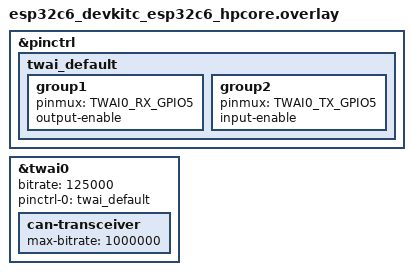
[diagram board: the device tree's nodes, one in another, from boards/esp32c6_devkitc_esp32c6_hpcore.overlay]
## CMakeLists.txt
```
# SPDX-License-Identifier: Apache-2.0

cmake_minimum_required(VERSION 3.20.0)
find_package(Zephyr REQUIRED HINTS $ENV{ZEPHYR_BASE})
project(app_more_services6)

zephyr_syscall_header(${CMAKE_CURRENT_SOURCE_DIR}/src/svc.h)

target_sources(app PRIVATE src/main.c src/svc.c)
```

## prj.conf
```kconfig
CONFIG_USERSPACE=y
CONFIG_APPLICATION_DEFINED_SYSCALL=y

CONFIG_CAN=y

CONFIG_LOG=y
CONFIG_LOG_MODE_MINIMAL=y
CONFIG_THREAD_NAME=y

CONFIG_MAIN_STACK_SIZE=4096
```

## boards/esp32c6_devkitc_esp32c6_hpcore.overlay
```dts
/*
 * Copyright (c) 2026 Espressif Systems (Shanghai) Co., Ltd.
 *
 * SPDX-License-Identifier: Apache-2.0
 */

#include <zephyr/dt-bindings/pinctrl/esp32c6-pinctrl.h>

/*
 * CAN/TWAI internal loopback: TX and RX are both muxed to GPIO5 (output and
 * input enabled on the same pin) so a sent frame is wired straight back to the
 * receiver. No external transceiver or bus is needed.
 */
&pinctrl {
	twai_default: twai_default {
		group1 {
			pinmux = <TWAI0_RX_GPIO5>;
			output-enable;
		};

		group2 {
			pinmux = <TWAI0_TX_GPIO5>;
			input-enable;
		};
	};
};

&twai0 {
	status = "okay";
	bitrate = <125000>;
	pinctrl-0 = <&twai_default>;
	pinctrl-names = "default";

	can-transceiver {
		max-bitrate = <1000000>;
	};
};
```

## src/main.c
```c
/*
 * Copyright (c) 2026 Espressif Systems (Shanghai) Co., Ltd.
 *
 * SPDX-License-Identifier: Apache-2.0
 */

/*
 * An app using the CAN bus through services from user mode. The platform owns
 * the controller, puts it in loopback, installs a receive filter feeding a
 * per-app queue, and starts it. The app sends frames and polls received ones,
 * passing only a scalar id and a byte payload across the user/kernel boundary.
 * Loopback echoes each sent frame back, so the demo runs with no wiring.
 */

#include "svc.h"

#include <zephyr/kernel.h>
#include <zephyr/sys/printk.h>

#define STACK_SIZE 2048
#define APP_PRIO   5

K_THREAD_STACK_DEFINE(app_stack, STACK_SIZE);
static struct k_thread app_thread;

static void app_entry(void *p1, void *p2, void *p3)
{
	ARG_UNUSED(p1); ARG_UNUSED(p2); ARG_UNUSED(p3);

	for (int round = 0; round < 4; round++) {
		uint8_t tx[4] = { 0x10 + round, 0x20, 0x30, 0x40 };
		uint32_t id = 0x123 + round;

		int sent = svc_can_send(id, tx, sizeof(tx));

		printk("  [app] round %d: sent id=0x%03x len=%d\n", round, id, sent);

		/* Give the loopback frame a moment to land in the queue. */
		k_msleep(50);

		uint32_t rid = 0;
		uint8_t rx[8] = { 0 };
		int n = svc_can_recv(&rid, rx, sizeof(rx));

		if (n >= 0) {
			printk("  [app] recv id=0x%03x len=%d data=", rid, n);
			for (int i = 0; i < n; i++) {
				printk("%02x ", rx[i]);
			}
			printk("\n");
		} else {
			printk("  [app] recv rc=%d\n", n);
		}

		k_msleep(300);
	}

	printk("  [app] done - used CAN send + receive\n");
}

int main(void)
{
	printk("\n*** more services 6: CAN bus (C6) ***\n");

	svc_can_install();

	k_tid_t t = k_thread_create(&app_thread, app_stack, STACK_SIZE, app_entry,
				    NULL, NULL, NULL, APP_PRIO, K_USER, K_FOREVER);

	k_thread_start(t);
	k_thread_join(t, K_FOREVER);

	printk("\n*** done ***\n");
	return 0;
}
```

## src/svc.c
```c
/*
 * Copyright (c) 2026 Espressif Systems (Shanghai) Co., Ltd.
 *
 * SPDX-License-Identifier: Apache-2.0
 */

#include "svc.h"

#include <zephyr/kernel.h>
#include <zephyr/device.h>
#include <zephyr/drivers/can.h>
#include <zephyr/internal/syscall_handler.h>
#include <string.h>
#include <errno.h>

#define CAN_PAYLOAD_MAX 8

/* The platform owns the CAN controller; the app reaches it through this seam. */
static const struct device *const can_dev = DEVICE_DT_GET(DT_NODELABEL(twai0));

/* Per-app receive queue: the platform's filter feeds frames here in S-mode. */
K_MSGQ_DEFINE(app_can_q, sizeof(struct can_frame), 8, 4);

void svc_can_install(void)
{
	if (!device_is_ready(can_dev)) {
		return;
	}

	/* Loopback self-test: a sent frame is received back, no bus needed. */
	(void)can_set_mode(can_dev, CAN_MODE_LOOPBACK);

	/* Accept every standard id; in a real grant this mask is scoped. */
	const struct can_filter filter = {
		.id = 0,
		.mask = 0,
		.flags = 0,
	};

	(void)can_add_rx_filter_msgq(can_dev, &app_can_q, &filter);
	(void)can_start(can_dev);
}

int z_impl_svc_can_send(uint32_t id, const uint8_t *buf, size_t len)
{
	if (!device_is_ready(can_dev) || len > CAN_PAYLOAD_MAX) {
		return -EINVAL;
	}

	struct can_frame frame = {
		.id = id,
		.dlc = (uint8_t)len,
		.flags = 0,
	};

	memcpy(frame.data, buf, len);

	int rc = can_send(can_dev, &frame, K_MSEC(100), NULL, NULL);

	return (rc == 0) ? (int)len : rc;
}

int z_impl_svc_can_recv(uint32_t *id_out, uint8_t *buf, size_t cap)
{
	struct can_frame frame;

	if (k_msgq_get(&app_can_q, &frame, K_NO_WAIT) != 0) {
		return -EAGAIN;
	}

	size_t n = MIN((size_t)frame.dlc, cap);

	*id_out = frame.id;
	memcpy(buf, frame.data, n);
	return (int)n;
}

#ifdef CONFIG_USERSPACE
static inline int z_vrfy_svc_can_send(uint32_t id, const uint8_t *buf, size_t len)
{
	if (len > CAN_PAYLOAD_MAX) {
		return -EINVAL;
	}
	K_OOPS(K_SYSCALL_MEMORY_READ(buf, len));
	return z_impl_svc_can_send(id, buf, len);
}
#include <zephyr/syscalls/svc_can_send_mrsh.c>

static inline int z_vrfy_svc_can_recv(uint32_t *id_out, uint8_t *buf, size_t cap)
{
	if (cap > CAN_PAYLOAD_MAX) {
		cap = CAN_PAYLOAD_MAX;
	}
	K_OOPS(K_SYSCALL_MEMORY_WRITE(id_out, sizeof(*id_out)));
	K_OOPS(K_SYSCALL_MEMORY_WRITE(buf, cap));
	return z_impl_svc_can_recv(id_out, buf, cap);
}
#include <zephyr/syscalls/svc_can_recv_mrsh.c>
#endif
```

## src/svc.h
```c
/*
 * Copyright (c) 2026 Espressif Systems (Shanghai) Co., Ltd.
 *
 * SPDX-License-Identifier: Apache-2.0
 */

#ifndef APP_MORE_SERVICES6_SVC_H_
#define APP_MORE_SERVICES6_SVC_H_

#include <zephyr/kernel.h>

/*
 * A sixth batch: the CAN bus, scoped to a granted message-id filter. The
 * platform owns the controller, sets its mode and bitrate, and installs a
 * receive filter that feeds a per-app queue. The app sends frames and polls
 * received ones; it never touches the driver frame struct - only scalar id and
 * a byte payload cross the user/kernel boundary.
 *
 *   svc_can_send - send a standard-id frame with @len payload bytes.
 *   svc_can_recv - poll the next received frame for this app; -EAGAIN if none.
 */

/* Scoped: send a standard 11-bit @id frame carrying @buf[0..len). */
__syscall int svc_can_send(uint32_t id, const uint8_t *buf, size_t len);

/*
 * Scoped: poll the next received frame. On success returns the payload length,
 * writes the id to *@id_out and up to @cap bytes into @buf. -EAGAIN if none.
 */
__syscall int svc_can_recv(uint32_t *id_out, uint8_t *buf, size_t cap);

/* Supervisor-only: set the controller mode, install the filter, and start. */
void svc_can_install(void);

#include <zephyr/syscalls/svc.h>

#endif /* APP_MORE_SERVICES6_SVC_H_ */
```
